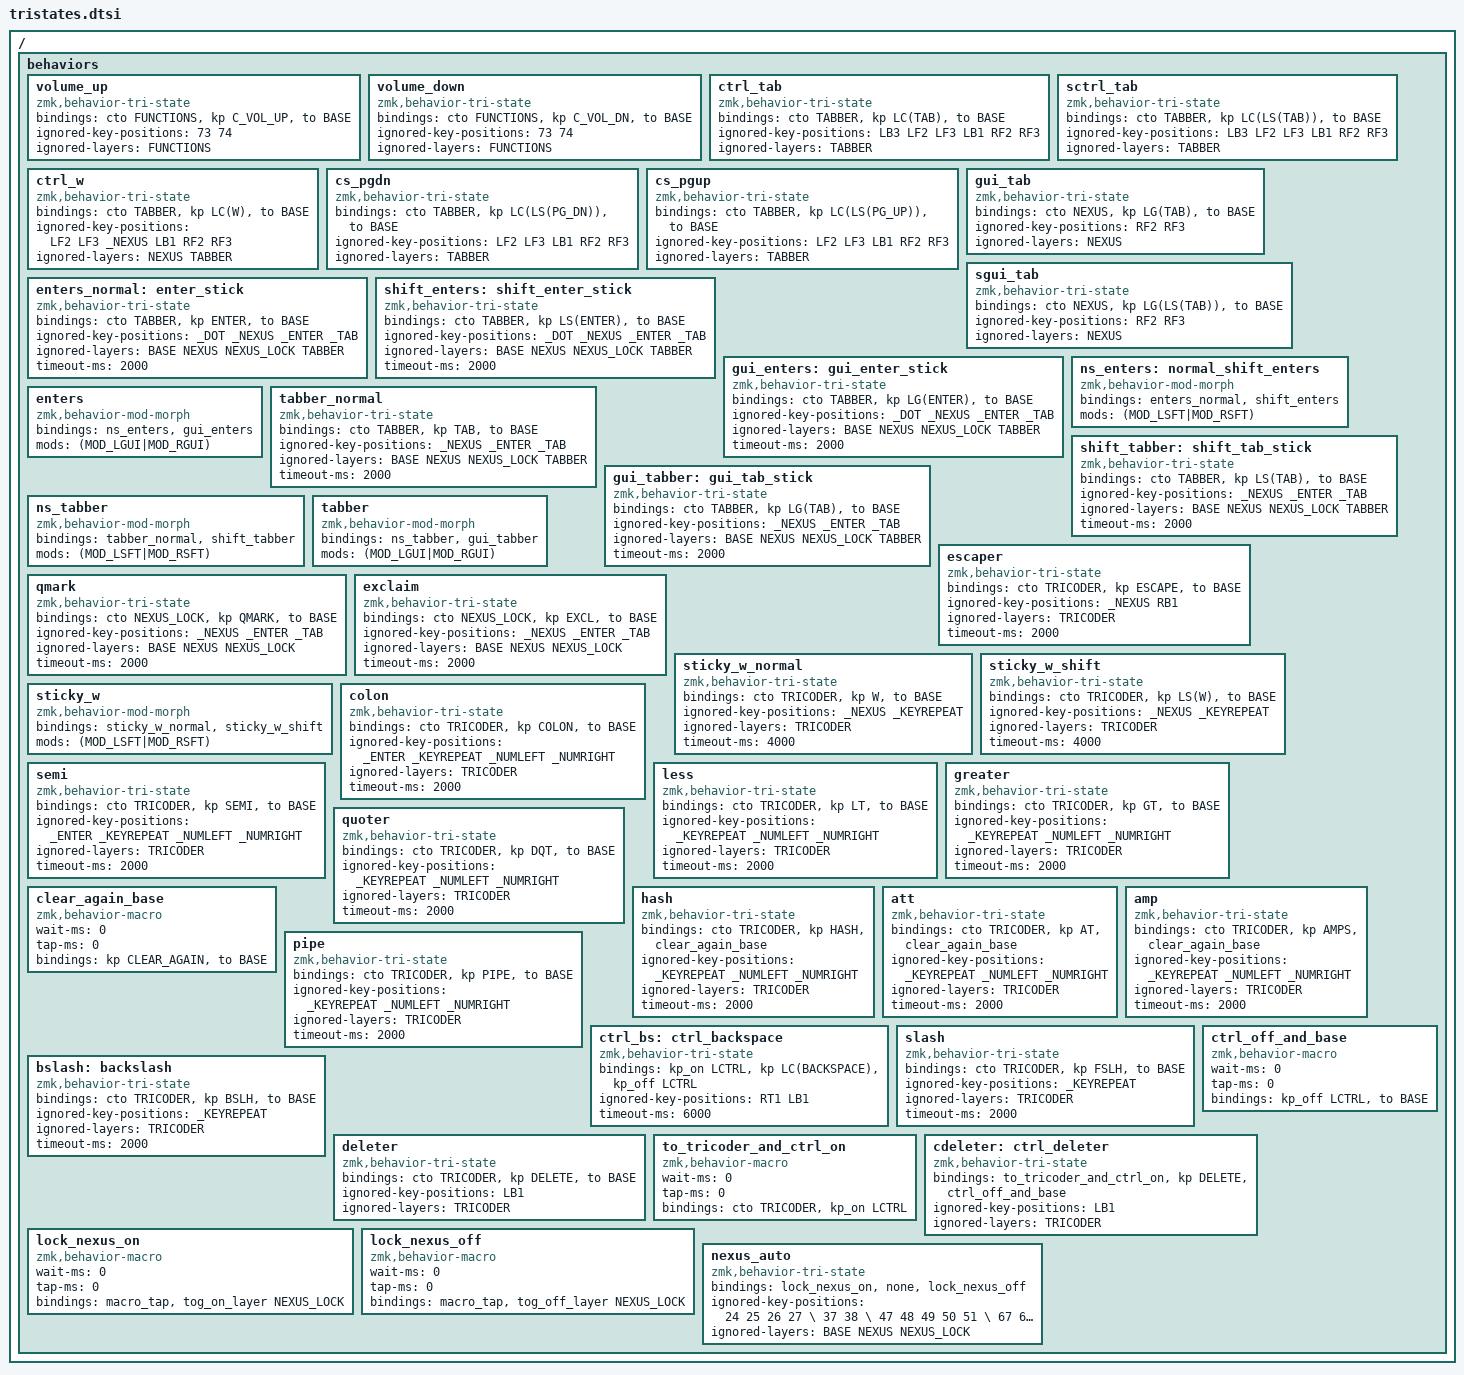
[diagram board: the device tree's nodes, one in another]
/ {
	behaviors {

    #define _DOT LB4
    #define _NEXUS LB3
    #define _ENTER LB2
    #define _TAB RM1
    #define _KEYREPEAT RM1
    #define _NUMLEFT LH6
    #define _NUMRIGHT RH6

		volume_up: volume_up {
				compatible = "zmk,behavior-tri-state";
				#binding-cells = <0>;
				bindings = <&cto FUNCTIONS>, <&kp C_VOL_UP>, <&to BASE>;
				ignored-key-positions = <73 74>;
				ignored-layers = <FUNCTIONS>;
		};

		volume_down: volume_down {
				compatible = "zmk,behavior-tri-state";
				#binding-cells = <0>;
				bindings = <&cto FUNCTIONS>, <&kp C_VOL_DN>, <&to BASE>;
				ignored-key-positions = <73 74>;
				ignored-layers = <FUNCTIONS>;
		};

		ctrl_tab: ctrl_tab {
				compatible = "zmk,behavior-tri-state";
				#binding-cells = <0>;
				bindings = <&cto TABBER>, <&kp LC(TAB)>, <&to BASE>;
				ignored-key-positions = <LB3 LF2 LF3 LB1 RF2 RF3>;
				ignored-layers = <TABBER>;
		};

		sctrl_tab: sctrl_tab {
				compatible = "zmk,behavior-tri-state";
				#binding-cells = <0>;
				bindings = <&cto TABBER>, <&kp LC(LS(TAB))>, <&to BASE>;
				ignored-key-positions = <LB3 LF2 LF3 LB1 RF2 RF3>;
				ignored-layers = <TABBER>;
		};

		ctrl_w: ctrl_w {
				compatible = "zmk,behavior-tri-state";
				#binding-cells = <0>;
				bindings = <&cto TABBER>, <&kp LC(W)>, <&to BASE>;
				ignored-key-positions = <LF2 LF3 _NEXUS LB1 RF2 RF3>;
				ignored-layers = <NEXUS TABBER>;
		};

		cs_pgdn: cs_pgdn {
				compatible = "zmk,behavior-tri-state";
				#binding-cells = <0>;
				bindings = <&cto TABBER>, <&kp LC(LS(PG_DN))>, <&to BASE>;
				ignored-key-positions = <LF2 LF3 LB1 RF2 RF3>;
				ignored-layers = <TABBER>;
		};

		cs_pgup: cs_pgup {
				compatible = "zmk,behavior-tri-state";
				#binding-cells = <0>;
				bindings = <&cto TABBER>, <&kp LC(LS(PG_UP))>, <&to BASE>;
				ignored-key-positions = <LF2 LF3 LB1 RF2 RF3>;
				ignored-layers = <TABBER>;
		};

		gui_tab: gui_tab {
				compatible = "zmk,behavior-tri-state";
				#binding-cells = <0>;
				bindings = <&cto NEXUS>, <&kp LG(TAB)>, <&to BASE>;
				ignored-key-positions = <RF2 RF3>;
				ignored-layers = <NEXUS>;
		};

		sgui_tab: sgui_tab {
				compatible = "zmk,behavior-tri-state";
				#binding-cells = <0>;
				bindings = <&cto NEXUS>, <&kp LG(LS(TAB))>, <&to BASE>;
				ignored-key-positions = <RF2 RF3>;
				ignored-layers = <NEXUS>;
		};

		enters_normal: enter_stick {
				compatible = "zmk,behavior-tri-state";
				#binding-cells = <0>;
				bindings = <&cto TABBER>, <&kp ENTER>, <&to BASE>;
				ignored-key-positions = <_DOT _NEXUS _ENTER _TAB>;
				ignored-layers = <BASE NEXUS NEXUS_LOCK TABBER>;
        timeout-ms = <2000>;
		};
    /* Ath, þetta er frekar bjánaleg lausn til að láta sticky shift virka með enter (handa inni mods virka augljóslega enn) */
		shift_enters: shift_enter_stick {
				compatible = "zmk,behavior-tri-state";
				#binding-cells = <0>;
				bindings = <&cto TABBER>, <&kp LS(ENTER)>, <&to BASE>;
				ignored-key-positions = <_DOT _NEXUS _ENTER _TAB>;
				ignored-layers = <BASE NEXUS NEXUS_LOCK TABBER>;
        timeout-ms = <2000>;
		};
		gui_enters: gui_enter_stick {
				compatible = "zmk,behavior-tri-state";
				#binding-cells = <0>;
				bindings = <&cto TABBER>, <&kp LG(ENTER)>, <&to BASE>;
				ignored-key-positions = <_DOT _NEXUS _ENTER _TAB>;
				ignored-layers = <BASE NEXUS NEXUS_LOCK TABBER>;
        timeout-ms = <2000>;
		};
		ns_enters: normal_shift_enters {
			compatible = "zmk,behavior-mod-morph";
			#binding-cells = <0>;
			bindings = <&enters_normal>, <&shift_enters>;
			mods = <(MOD_LSFT|MOD_RSFT)>;
		};
		enters: enters {
			compatible = "zmk,behavior-mod-morph";
			#binding-cells = <0>;
			bindings = <&ns_enters>, <&gui_enters>;
			mods = <(MOD_LGUI|MOD_RGUI)>;
		};

		tabber_normal: tabber_normal {
				compatible = "zmk,behavior-tri-state";
				#binding-cells = <0>;
				bindings = <&cto TABBER>, <&kp TAB>, <&to BASE>;
				ignored-key-positions = <_NEXUS _ENTER _TAB>;
				ignored-layers = <BASE NEXUS NEXUS_LOCK TABBER>;
        timeout-ms = <2000>;
		};
		shift_tabber: shift_tab_stick {
				compatible = "zmk,behavior-tri-state";
				#binding-cells = <0>;
				bindings = <&cto TABBER>, <&kp LS(TAB)>, <&to BASE>;
				ignored-key-positions = <_NEXUS _ENTER _TAB>;
				ignored-layers = <BASE NEXUS NEXUS_LOCK TABBER>;
        timeout-ms = <2000>;
		};
		gui_tabber: gui_tab_stick {
				compatible = "zmk,behavior-tri-state";
				#binding-cells = <0>;
				bindings = <&cto TABBER>, <&kp LG(TAB)>, <&to BASE>;
				ignored-key-positions = <_NEXUS _ENTER _TAB>;
				ignored-layers = <BASE NEXUS NEXUS_LOCK TABBER>;
        timeout-ms = <2000>;
		};
		ns_tabber: ns_tabber {
			compatible = "zmk,behavior-mod-morph";
			#binding-cells = <0>;
			bindings = <&tabber_normal>, <&shift_tabber>;
			mods = <(MOD_LSFT|MOD_RSFT)>;
		};
		tabber: tabber {
			compatible = "zmk,behavior-mod-morph";
			#binding-cells = <0>;
			bindings = <&ns_tabber>, <&gui_tabber>;
			mods = <(MOD_LGUI|MOD_RGUI)>;
		};

		escaper: escaper {
				compatible = "zmk,behavior-tri-state";
				#binding-cells = <0>;
				bindings = <&cto TRICODER>, <&kp ESCAPE>, <&to BASE>;
				ignored-key-positions = <_NEXUS RB1>;
				ignored-layers = <TRICODER>;
        timeout-ms = <2000>;
		};

		qmark: qmark {
				compatible = "zmk,behavior-tri-state";
				#binding-cells = <0>;
				bindings = <&cto NEXUS_LOCK>, <&kp QMARK>, <&to BASE>;
				ignored-key-positions = <_NEXUS _ENTER _TAB>;
				ignored-layers = <BASE NEXUS NEXUS_LOCK>;
        timeout-ms = <2000>;
		};

		exclaim: exclaim {
				compatible = "zmk,behavior-tri-state";
				#binding-cells = <0>;
				bindings = <&cto NEXUS_LOCK>, <&kp EXCL>, <&to BASE>;
				ignored-key-positions = <_NEXUS _ENTER _TAB>;
				ignored-layers = <BASE NEXUS NEXUS_LOCK>;
        timeout-ms = <2000>;
		};

		/* sticky_w_normal: sticky_w_normal { */
		sticky_w_normal: sticky_w_normal {
				compatible = "zmk,behavior-tri-state";
				#binding-cells = <0>;
				bindings = <&cto TRICODER>, <&kp W>, <&to BASE>;
				ignored-key-positions = <_NEXUS _KEYREPEAT>;
				ignored-layers = <TRICODER>;
        timeout-ms = <4000>;
		};
		sticky_w_shift: sticky_w_shift {
				compatible = "zmk,behavior-tri-state";
				#binding-cells = <0>;
				bindings = <&cto TRICODER>, <&kp LS(W)>, <&to BASE>;
				ignored-key-positions = <_NEXUS _KEYREPEAT>;
				ignored-layers = <TRICODER>;
		      timeout-ms = <4000>;
		};
		/* sticky_w_ctrl: sticky_w_ctrl { */
		/* 		compatible = "zmk,behavior-tri-state"; */
		/* 		#binding-cells = <0>; */
		/* 		bindings = <&cto NEXUS_LOCK>, <&kp LC(W)>, <&to BASE>; */
		/* 		ignored-key-positions = <_NEXUS LM2>; */
		/* 		ignored-layers = <BASE NEXUS NEXUS_LOCK>; */
		/*       timeout-ms = <2000>; */
		/* }; */
		sticky_w: sticky_w {
			compatible = "zmk,behavior-mod-morph";
			#binding-cells = <0>;
			bindings = <&sticky_w_normal>, <&sticky_w_shift>;
			mods = <(MOD_LSFT|MOD_RSFT)>;
		};

		colon: colon {
				compatible = "zmk,behavior-tri-state";
				#binding-cells = <0>;
				bindings = <&cto TRICODER>, <&kp COLON>, <&to BASE>;
				ignored-key-positions = <_ENTER _KEYREPEAT _NUMLEFT _NUMRIGHT>;
				ignored-layers = <TRICODER>;
        timeout-ms = <2000>;
		};

		semi: semi {
				compatible = "zmk,behavior-tri-state";
				#binding-cells = <0>;
				bindings = <&cto TRICODER>, <&kp SEMI>, <&to BASE>;
				ignored-key-positions = <_ENTER _KEYREPEAT _NUMLEFT _NUMRIGHT>;
				ignored-layers = <TRICODER>;
        timeout-ms = <2000>;
		};

		less: less {
				compatible = "zmk,behavior-tri-state";
				#binding-cells = <0>;
				bindings = <&cto TRICODER>, <&kp LT>, <&to BASE>;
				ignored-key-positions = <_KEYREPEAT _NUMLEFT _NUMRIGHT>;
				ignored-layers = <TRICODER>;
        timeout-ms = <2000>;
		};

		greater: greater {
				compatible = "zmk,behavior-tri-state";
				#binding-cells = <0>;
				bindings = <&cto TRICODER>, <&kp GT>, <&to BASE>;
				ignored-key-positions = <_KEYREPEAT _NUMLEFT _NUMRIGHT>;
				ignored-layers = <TRICODER>;
        timeout-ms = <2000>;
		};

		quoter: quoter {
				compatible = "zmk,behavior-tri-state";
				#binding-cells = <0>;
				bindings = <&cto TRICODER>, <&kp DQT>, <&to BASE>;
				ignored-key-positions = <_KEYREPEAT _NUMLEFT _NUMRIGHT>;
				ignored-layers = <TRICODER>;
        timeout-ms = <2000>;
		};

		clear_again_base: clear_again_base {
			compatible = "zmk,behavior-macro";
			#binding-cells = <0>;
			wait-ms = <0>;
			tap-ms = <0>;
			bindings = <&kp CLEAR_AGAIN>, <&to BASE>;
		};

		hash: hash {
				compatible = "zmk,behavior-tri-state";
				#binding-cells = <0>;
				bindings = <&cto TRICODER>, <&kp HASH>, <&clear_again_base>;
				ignored-key-positions = <_KEYREPEAT _NUMLEFT _NUMRIGHT>;
				ignored-layers = <TRICODER>;
        timeout-ms = <2000>;
		};

		att: att {
				compatible = "zmk,behavior-tri-state";
				#binding-cells = <0>;
				bindings = <&cto TRICODER>, <&kp AT>, <&clear_again_base>;
				ignored-key-positions = <_KEYREPEAT _NUMLEFT _NUMRIGHT>;
				ignored-layers = <TRICODER>;
        timeout-ms = <2000>;
		};

		amp: amp {
				compatible = "zmk,behavior-tri-state";
				#binding-cells = <0>;
				bindings = <&cto TRICODER>, <&kp AMPS>, <&clear_again_base>;
				ignored-key-positions = <_KEYREPEAT _NUMLEFT _NUMRIGHT>;
				ignored-layers = <TRICODER>;
        timeout-ms = <2000>;
		};

		pipe: pipe {
				compatible = "zmk,behavior-tri-state";
				#binding-cells = <0>;
				bindings = <&cto TRICODER>, <&kp PIPE>, <&to BASE>;
				ignored-key-positions = <_KEYREPEAT _NUMLEFT _NUMRIGHT>;
				ignored-layers = <TRICODER>;
        timeout-ms = <2000>;
		};

		ctrl_bs: ctrl_backspace {
				compatible = "zmk,behavior-tri-state";
				#binding-cells = <0>;
				bindings = <&kp_on LCTRL>, <&kp LC(BACKSPACE)>, <&kp_off LCTRL>;
				ignored-key-positions = <RT1 LB1>;
				/* ignored-layers = <TRICODER>; */
        timeout-ms = <6000>;
		};

		slash: slash {
				compatible = "zmk,behavior-tri-state";
				#binding-cells = <0>;
				bindings = <&cto TRICODER>, <&kp FSLH>, <&to BASE>;
				ignored-key-positions = <_KEYREPEAT>;
				ignored-layers = <TRICODER>;
        timeout-ms = <2000>;
		};
    
	  bslash: backslash {
				compatible = "zmk,behavior-tri-state";
				#binding-cells = <0>;
				bindings = <&cto TRICODER>, <&kp BSLH>, <&to BASE>;
				ignored-key-positions = <_KEYREPEAT>;
				ignored-layers = <TRICODER>;
        timeout-ms = <2000>;
		};

		deleter: deleter {
				compatible = "zmk,behavior-tri-state";
				#binding-cells = <0>;
				bindings = <&cto TRICODER>, <&kp DELETE>, <&to BASE>;
				ignored-key-positions = <LB1>;
				ignored-layers = <TRICODER>;
		};


		to_tricoder_and_ctrl_on: to_tricoder_and_ctrl_on {
			compatible = "zmk,behavior-macro";
			#binding-cells = <0>;
			wait-ms = <0>;
			tap-ms = <0>;
			bindings = <&cto TRICODER>, <&kp_on LCTRL>;
		};

		ctrl_off_and_base: ctrl_off_and_base {
			compatible = "zmk,behavior-macro";
			#binding-cells = <0>;
			wait-ms = <0>;
			tap-ms = <0>;
			bindings = <&kp_off LCTRL>, <&to BASE>;
		};

		cdeleter: ctrl_deleter {
				compatible = "zmk,behavior-tri-state";
				#binding-cells = <0>;
				bindings = <&to_tricoder_and_ctrl_on>, <&kp DELETE>, <&ctrl_off_and_base>;
				ignored-key-positions = <LB1>;
				ignored-layers = <TRICODER>;
		};

    lock_nexus_on: lock_nexus_on {
        compatible = "zmk,behavior-macro";
        #binding-cells = <0>;
        wait-ms = <0>;
        tap-ms = <0>;
        bindings = <&macro_tap &tog_on_layer NEXUS_LOCK>; // Uses Toggle, which survives the roll
    };
    lock_nexus_off: lock_nexus_off {
        compatible = "zmk,behavior-macro";
        #binding-cells = <0>;
        wait-ms = <0>;
        tap-ms = <0>;
        bindings = <&macro_tap &tog_off_layer NEXUS_LOCK>;
    };
		nexus_auto: nexus_auto {
			compatible = "zmk,behavior-tri-state";
			#binding-cells = <0>;
			bindings = <&lock_nexus_on>, <&none>, <&lock_nexus_off>;
			ignored-key-positions = <
			
		  /* left */
		      24 25 26 27    \
		         37 38       \
		   47 48 49 50 51    \
		         67 68
		  /* right */
		16    18          \
		28 29 30 31       \
		40 41 42 43 44 45 \
		58 59 60 61 62    \
		75 76         
		  /* thumbs, 69 er space og 74 er R */
		   52          74             \
		 70           73                 \
		  71         72

			>;
				ignored-layers = <BASE NEXUS NEXUS_LOCK>;
		};


		/*   left */
		/* 0  1  2  3  4       \ */
		/* 10 11 12 13 14 15    \ */
		/* 22 23 24 25 26 27    \ */
		/* 34 35 36 37 38 39    \ */
		/* 46 47 48 49 50 51    \ */
		/* 64 65 66 67 68 */
		/*   right */
		/* 5  6  7  8  9 \ */
		/* 16 17 18 19 20 21 \ */
		/* 28 29 30 31 32 33 \ */
		/* 40 41 42 43 44 45 \ */
		/* 58 59 60 61 62 63 \ */
		/* 75 76 77 78 79 */
		/*   thumbs, 69 er space og 74 er R */
		/* 69 52       57 74                \ */
		/*  70 53     56 73                 \ */
		/*   71 54   55 72 */

		/* cskctrl: cskctrl { */
		/* 		compatible = "zmk,behavior-tri-state"; */
		/* 		#binding-cells = <0>; */
		/* 		bindings = <&cto OVERMODS>, <&sk LCTRL>, <&to BASE>; */
		/* 		ignored-key-positions = <LF2 LF3 LF4 RF2 RF3 RF4 LH6 RH6>; */
		/* 		ignored-layers = <OVERMODS>; */
		/* }; */
		/**/
		/* cskgui: cskgui { */
		/* 		compatible = "zmk,behavior-tri-state"; */
		/* 		#binding-cells = <0>; */
		/* 		bindings = <&cto OVERMODS>, <&sk LGUI>, <&to BASE>; */
		/* 		ignored-key-positions = <LF2 LF3 LF4 RF2 RF3 RF4 LH6 RH6>; */
		/* 		ignored-layers = <OVERMODS>; */
		/* }; */
		/**/
		/* cskalt: cskalt { */
		/* 		compatible = "zmk,behavior-tri-state"; */
		/* 		#binding-cells = <0>; */
		/* 		bindings = <&cto OVERMODS>, <&sk LALT>, <&to BASE>; */
		/* 		ignored-key-positions = <LF2 LF3 LF4 RF2 RF3 RF4 LH6 RH6>; */
		/* 		ignored-layers = <OVERMODS>; */
		/* }; */
		/**/
		/* cskshift: cskshift { */
		/* 		compatible = "zmk,behavior-tri-state"; */
		/* 		#binding-cells = <0>; */
		/* 		bindings = <&cto OVERMODS>, <&sk LSHIFT>, <&to BASE>; */
		/* 		ignored-key-positions = <LF2 LF3 LF4 RF2 RF3 RF4 LH6 RH6>; */
		/* 		ignored-layers = <OVERMODS>; */
		/* }; */
		/**/
		/* skctrl: skctrl { */
		/* 		compatible = "zmk,behavior-tri-state"; */
		/* 		#binding-cells = <0>; */
		/* 		bindings = <&to OVERMODS>, <&sk LCTRL>, <&to BASE>; */
		/* 		ignored-key-positions = <LF2 LF3 LF4 RF2 RF3 RF4 LH6 RH6>; */
		/* 		ignored-layers = <OVERMODS>; */
		/* }; */
		/**/
		/* skgui: skgui { */
		/* 		compatible = "zmk,behavior-tri-state"; */
		/* 		#binding-cells = <0>; */
		/* 		bindings = <&to OVERMODS>, <&sk LGUI>, <&to BASE>; */
		/* 		ignored-key-positions = <LF2 LF3 LF4 RF2 RF3 RF4 LH6 RH6>; */
		/* 		ignored-layers = <OVERMODS>; */
		/* }; */
		/**/
		/* skalt: skalt { */
		/* 		compatible = "zmk,behavior-tri-state"; */
		/* 		#binding-cells = <0>; */
		/* 		bindings = <&to OVERMODS>, <&sk LALT>, <&to BASE>; */
		/* 		ignored-key-positions = <LF2 LF3 LF4 RF2 RF3 RF4 LH6 RH6>; */
		/* 		ignored-layers = <OVERMODS>; */
		/* }; */
		/**/
		/* skshift: skshift { */
		/* 		compatible = "zmk,behavior-tri-state"; */
		/* 		#binding-cells = <0>; */
		/* 		bindings = <&to OVERMODS>, <&sk LSHIFT>, <&to BASE>; */
		/* 		ignored-key-positions = <LF2 LF3 LF4 RF2 RF3 RF4 LH6 RH6>; */
		/* 		ignored-layers = <OVERMODS>; */
		/* }; */


	};
};
